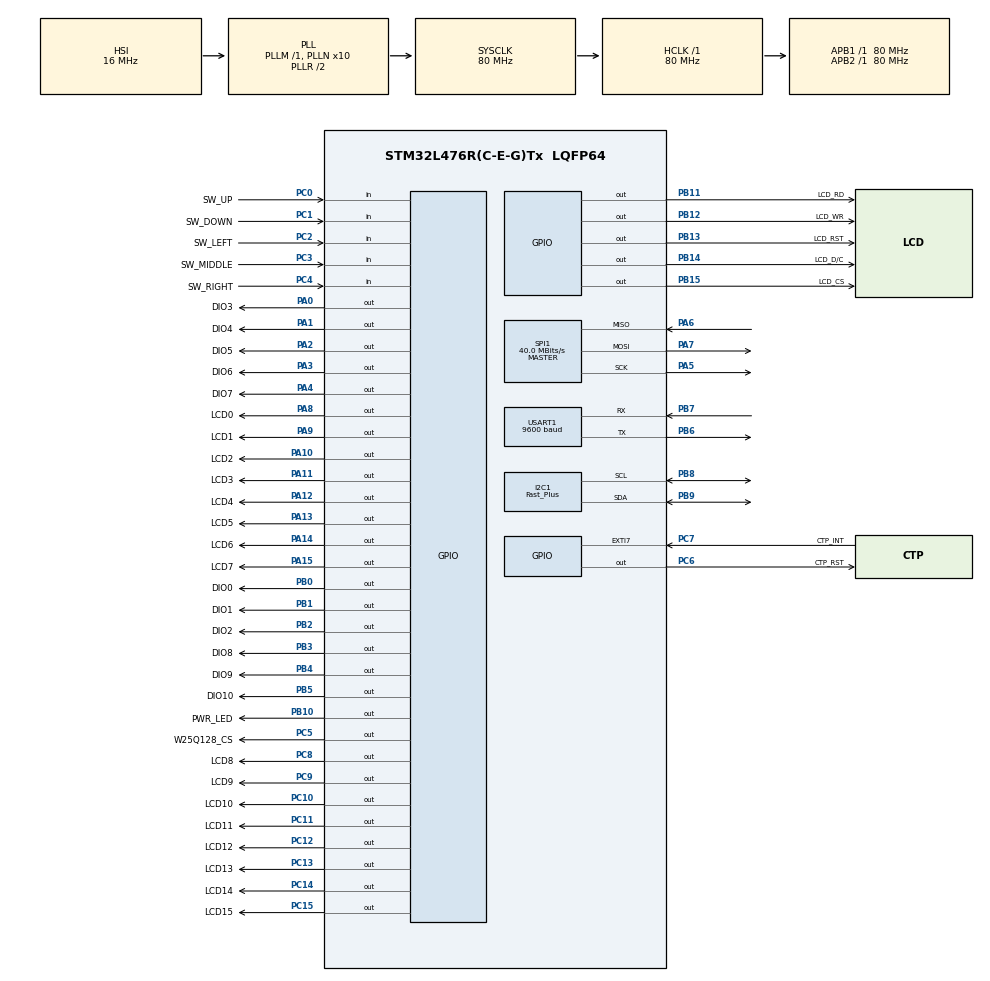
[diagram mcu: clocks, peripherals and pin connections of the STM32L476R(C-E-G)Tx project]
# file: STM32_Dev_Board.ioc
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FREERTOS.Tasks01=defaultTask,-3,128,StartDefaultTask,Default,NULL,Dynamic,NULL,NULL
FREERTOS.configTOTAL_HEAP_SIZE=20000
FREERTOS.configUSE_NEWLIB_REENTRANT=1
I2C1.I2C_Speed_Mode=I2C_Fast_Plus
I2C1.Timing=0x00300F33
Mcu.Family=STM32L4
Mcu.Name=STM32L476R(C-E-G)Tx
Mcu.Package=LQFP64
NVIC.EXTI9_5_IRQn=true\:5\:0\:true\:false\:true\:true\:true\:true\:true
NVIC.PriorityGroup=NVIC_PRIORITYGROUP_4
NVIC.TIM1_UP_TIM16_IRQn=true\:15\:0\:false\:false\:true\:false\:false\:true\:true
NVIC.TimeBase=TIM1_UP_TIM16_IRQn
NVIC.TimeBaseIP=TIM1
PA0.GPIO_Label=DIO3
PA0.Signal=GPIO_Output
PA1.GPIO_Label=DIO4
PA1.Signal=GPIO_Output
PA10.GPIO_Label=LCD2
PA10.Signal=GPIO_Output
PA11.GPIO_Label=LCD3
PA11.Signal=GPIO_Output
PA12.GPIO_Label=LCD4
PA12.Signal=GPIO_Output
PA13\ (JTMS-SWDIO).GPIO_Label=LCD5
PA13\ (JTMS-SWDIO).Signal=GPIO_Output
PA14\ (JTCK-SWCLK).GPIO_Label=LCD6
PA14\ (JTCK-SWCLK).Signal=GPIO_Output
PA15\ (JTDI).GPIO_Label=LCD7
PA15\ (JTDI).Signal=GPIO_Output
PA2.GPIO_Label=DIO5
PA2.Signal=GPIO_Output
PA3.GPIO_Label=DIO6
PA3.Signal=GPIO_Output
PA4.GPIO_Label=DIO7
PA4.Signal=GPIO_Output
PA5.Mode=Full_Duplex_Master
PA5.Signal=SPI1_SCK
PA6.Mode=Full_Duplex_Master
PA6.Signal=SPI1_MISO
PA7.Mode=Full_Duplex_Master
PA7.Signal=SPI1_MOSI
PA8.GPIO_Label=LCD0
PA8.Signal=GPIO_Output
PA9.GPIO_Label=LCD1
PA9.Signal=GPIO_Output
PB0.GPIO_Label=DIO0
PB0.Signal=GPIO_Output
PB1.GPIO_Label=DIO1
PB1.Signal=GPIO_Output
PB10.GPIO_Label=PWR_LED
PB10.Signal=GPIO_Output
PB11.GPIO_Label=LCD_RD
PB11.Signal=GPIO_Output
PB12.GPIO_Label=LCD_WR
PB12.Signal=GPIO_Output
PB13.GPIO_Label=LCD_RST
PB13.Signal=GPIO_Output
PB14.GPIO_Label=LCD_D/C
PB14.Signal=GPIO_Output
PB15.GPIO_Label=LCD_CS
PB15.Signal=GPIO_Output
PB2.GPIO_Label=DIO2
PB2.Signal=GPIO_Output
PB3\ (JTDO-TRACESWO).GPIO_Label=DIO8
PB3\ (JTDO-TRACESWO).Signal=GPIO_Output
PB4\ (NJTRST).GPIO_Label=DIO9
PB4\ (NJTRST).Signal=GPIO_Output
PB5.GPIO_Label=DIO10
PB5.Signal=GPIO_Output
PB6.Mode=Asynchronous
PB6.Signal=USART1_TX
PB7.Mode=Asynchronous
PB7.Signal=USART1_RX
PB8.Mode=I2C
PB8.Signal=I2C1_SCL
PB9.Mode=I2C
PB9.Signal=I2C1_SDA
PC0.GPIO_Label=SW_UP
PC0.Signal=GPIO_Input
PC1.GPIO_Label=SW_DOWN
PC1.Signal=GPIO_Input
PC10.GPIO_Label=LCD10
PC10.Signal=GPIO_Output
PC11.GPIO_Label=LCD11
PC11.Signal=GPIO_Output
PC12.GPIO_Label=LCD12
PC12.Signal=GPIO_Output
PC13.GPIO_Label=LCD13
PC13.Signal=GPIO_Output
PC14-OSC32_IN\ (PC14).GPIO_Label=LCD14
PC14-OSC32_IN\ (PC14).Signal=GPIO_Output
PC15-OSC32_OUT\ (PC15).GPIO_Label=LCD15
PC15-OSC32_OUT\ (PC15).Signal=GPIO_Output
PC2.GPIO_Label=SW_LEFT
PC2.Signal=GPIO_Input
PC3.GPIO_Label=SW_MIDDLE
PC3.Signal=GPIO_Input
PC4.GPIO_Label=SW_RIGHT
PC4.Signal=GPIO_Input
PC5.GPIO_Label=W25Q128_CS
PC5.Signal=GPIO_Output
PC6.GPIO_Label=CTP_RST
PC6.GPIO_PuPd=GPIO_NOPULL
PC6.PinState=GPIO_PIN_SET
PC6.Signal=GPIO_Output
PC7.GPIO_Label=CTP_INT
PC7.GPIO_ModeDefaultEXTI=GPIO_MODE_IT_RISING
PC7.GPIO_PuPd=GPIO_NOPULL
PC7.Signal=GPXTI7
PC8.GPIO_Label=LCD8
PC8.Signal=GPIO_Output
PC9.GPIO_Label=LCD9
PC9.Signal=GPIO_Output
ProjectManager.HeapSize=0x200
ProjectManager.StackSize=0x400
ProjectManager.TargetToolchain=STM32CubeIDE
RCC.ADCFreq_Value=64000000
RCC.AHBFreq_Value=80000000
RCC.APB1Freq_Value=80000000
RCC.APB1TimFreq_Value=80000000
RCC.APB2Freq_Value=80000000
RCC.APB2TimFreq_Value=80000000
RCC.CortexFreq_Value=80000000
RCC.HCLKFreq_Value=80000000
RCC.HSE_VALUE=8000000
RCC.HSI_VALUE=16000000
RCC.LSE_VALUE=32768
RCC.MSI_VALUE=4000000
RCC.PLLN=10
RCC.PLLSourceVirtual=RCC_PLLSOURCE_HSI
RCC.SYSCLKFreq_VALUE=80000000
RCC.SYSCLKSource=RCC_SYSCLKSOURCE_PLLCLK
RCC.USBFreq_Value=64000000
RCC.VCOOutputFreq_Value=160000000
SPI1.BaudRatePrescaler=SPI_BAUDRATEPRESCALER_2
SPI1.CalculateBaudRate=40.0 MBits/s
SPI1.Direction=SPI_DIRECTION_2LINES
SPI1.Mode=SPI_MODE_MASTER
SPI1.VirtualType=VM_MASTER
STMicroelectronics.X-CUBE-TOUCHGFX.4.20.0.tgfx_custom_height=320
STMicroelectronics.X-CUBE-TOUCHGFX.4.20.0.tgfx_custom_width=480
STMicroelectronics.X-CUBE-TOUCHGFX.4.20.0.tgfx_oswrapper=CMSIS V2
STMicroelectronics.X-CUBE-TOUCHGFX.4.20.0_IsPackSelfContextualization=true
USART1.BaudRate=9600
USART1.MSBFirstParam=ADVFEATURE_MSBFIRST_DISABLE
USART1.VirtualMode-Asynchronous=VM_ASYNC
USART1.WordLength=WORDLENGTH_8B
VP_CRC_VS_CRC.Mode=CRC_Activate
VP_FREERTOS_VS_CMSIS_V1.Mode=CMSIS_V1
VP_SYS_VS_tim1.Mode=TIM1
board=custom

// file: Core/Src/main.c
/* USER CODE BEGIN Header */
/**
  ******************************************************************************
  * @file           : main.c
  * @brief          : Main program body
  ******************************************************************************
  * @attention
  *
  * Copyright (c) 2022 STMicroelectronics.
  * All rights reserved.
  *
  * This software is licensed under terms that can be found in the LICENSE file
  * in the root directory of this software component.
  * If no LICENSE file comes with this software, it is provided AS-IS.
  *
  ******************************************************************************
  */
/* USER CODE END Header */
#include "main.h"
#include "cmsis_os.h"
#include "drivers/FT5446.h"

/* USER CODE BEGIN Includes */
#include "DevBoard.h"

/* USER CODE END Includes */

CRC_HandleTypeDef hcrc;

I2C_HandleTypeDef hi2c1;

SPI_HandleTypeDef hspi1;

UART_HandleTypeDef huart1;

osThreadId defaultTaskHandle;

void SystemClock_Config(void);
static void MX_GPIO_Init(void);
static void MX_I2C1_Init(void);
static void MX_SPI1_Init(void);
static void MX_USART1_UART_Init(void);
static void MX_CRC_Init(void);
void StartDefaultTask(void const * argument);

/* USER CODE BEGIN 0 */

//CTP Interrupt Callback function
void HAL_GPIO_EXTI_Callback(uint16_t GPIO_Pin)
{
	//Touch screen interrupt has occured. Notify the touch screen thread.
	xTaskNotifyFromISR( touchTaskHandle, 0, eSetValueWithOverwrite, pdFALSE);
}

/* USER CODE END 0 */

int main(void)
{

  /* MCU Configuration--------------------------------------------------------*/

  /* Reset of all peripherals, Initializes the Flash interface and the Systick. */
  HAL_Init();

  /* Configure the system clock */
  SystemClock_Config();

  /* Initialize all configured peripherals */
  MX_GPIO_Init();
  MX_I2C1_Init();
  MX_SPI1_Init();
  MX_USART1_UART_Init();
  MX_CRC_Init();
  /* USER CODE BEGIN 2 */

  /*
   * Low level initialisations
   */
  //Turn the Power LED on
  HAL_GPIO_WritePin(PWR_LED_GPIO_Port, PWR_LED_Pin, GPIO_PIN_SET);

  //Initialise the display using the display manager
  DM_Init();

  //Bring the CTP out of reset
  //Dont' forget that the top half of PORTC is used by the LCD Data
  HAL_GPIO_WritePin(CTP_RST_GPIO_Port, CTP_RST_Pin, GPIO_PIN_SET);
  HAL_Delay(10);

  FT5446_init();

  /* USER CODE END 2 */

  /* Create the thread(s) */
  /* definition and creation of defaultTask */
  osThreadDef(defaultTask, StartDefaultTask, osPriorityIdle, 0, 128);
  defaultTaskHandle = osThreadCreate(osThread(defaultTask), NULL);

  /* USER CODE BEGIN RTOS_THREADS */

  //Initialise the threads which run the peripherals on this board
  DevBoardBegin();

  /* USER CODE END RTOS_THREADS */

  /* Start scheduler */
  osKernelStart();

  /* We should never get here as control is now taken by the scheduler */
  /* Infinite loop */
  while (1)
  {

  }
}

void SystemClock_Config(void)
{
  RCC_OscInitTypeDef RCC_OscInitStruct = {0};
  RCC_ClkInitTypeDef RCC_ClkInitStruct = {0};

  /** Configure the main internal regulator output voltage
  */
  if (HAL_PWREx_ControlVoltageScaling(PWR_REGULATOR_VOLTAGE_SCALE1) != HAL_OK)
  {
    Error_Handler();
  }

  /** Initializes the RCC Oscillators according to the specified parameters
  * in the RCC_OscInitTypeDef structure.
  */
  RCC_OscInitStruct.OscillatorType = RCC_OSCILLATORTYPE_HSI;
  RCC_OscInitStruct.HSIState = RCC_HSI_ON;
  RCC_OscInitStruct.HSICalibrationValue = RCC_HSICALIBRATION_DEFAULT;
  RCC_OscInitStruct.PLL.PLLState = RCC_PLL_ON;
  RCC_OscInitStruct.PLL.PLLSource = RCC_PLLSOURCE_HSI;
  RCC_OscInitStruct.PLL.PLLM = 1;
  RCC_OscInitStruct.PLL.PLLN = 10;
  RCC_OscInitStruct.PLL.PLLP = RCC_PLLP_DIV7;
  RCC_OscInitStruct.PLL.PLLQ = RCC_PLLQ_DIV2;
  RCC_OscInitStruct.PLL.PLLR = RCC_PLLR_DIV2;
  if (HAL_RCC_OscConfig(&RCC_OscInitStruct) != HAL_OK)
  {
    Error_Handler();
  }

  /** Initializes the CPU, AHB and APB buses clocks
  */
  RCC_ClkInitStruct.ClockType = RCC_CLOCKTYPE_HCLK|RCC_CLOCKTYPE_SYSCLK
                              |RCC_CLOCKTYPE_PCLK1|RCC_CLOCKTYPE_PCLK2;
  RCC_ClkInitStruct.SYSCLKSource = RCC_SYSCLKSOURCE_PLLCLK;
  RCC_ClkInitStruct.AHBCLKDivider = RCC_SYSCLK_DIV1;
  RCC_ClkInitStruct.APB1CLKDivider = RCC_HCLK_DIV1;
  RCC_ClkInitStruct.APB2CLKDivider = RCC_HCLK_DIV1;

  if (HAL_RCC_ClockConfig(&RCC_ClkInitStruct, FLASH_LATENCY_4) != HAL_OK)
  {
    Error_Handler();
  }
}

static void MX_CRC_Init(void)
{

  hcrc.Instance = CRC;
  hcrc.Init.DefaultPolynomialUse = DEFAULT_POLYNOMIAL_ENABLE;
  hcrc.Init.DefaultInitValueUse = DEFAULT_INIT_VALUE_ENABLE;
  hcrc.Init.InputDataInversionMode = CRC_INPUTDATA_INVERSION_NONE;
  hcrc.Init.OutputDataInversionMode = CRC_OUTPUTDATA_INVERSION_DISABLE;
  hcrc.InputDataFormat = CRC_INPUTDATA_FORMAT_BYTES;
  if (HAL_CRC_Init(&hcrc) != HAL_OK)
  {
    Error_Handler();
  }

}

static void MX_I2C1_Init(void)
{

  hi2c1.Instance = I2C1;
  hi2c1.Init.Timing = 0x10909CEC;
  hi2c1.Init.OwnAddress1 = 0;
  hi2c1.Init.AddressingMode = I2C_ADDRESSINGMODE_7BIT;
  hi2c1.Init.DualAddressMode = I2C_DUALADDRESS_DISABLE;
  hi2c1.Init.OwnAddress2 = 0;
  hi2c1.Init.OwnAddress2Masks = I2C_OA2_NOMASK;
  hi2c1.Init.GeneralCallMode = I2C_GENERALCALL_DISABLE;
  hi2c1.Init.NoStretchMode = I2C_NOSTRETCH_DISABLE;
  if (HAL_I2C_Init(&hi2c1) != HAL_OK)
  {
    Error_Handler();
  }

  /** Configure Analogue filter
  */
  if (HAL_I2CEx_ConfigAnalogFilter(&hi2c1, I2C_ANALOGFILTER_ENABLE) != HAL_OK)
  {
    Error_Handler();
  }

  /** Configure Digital filter
  */
  if (HAL_I2CEx_ConfigDigitalFilter(&hi2c1, 0) != HAL_OK)
  {
    Error_Handler();
  }

}

static void MX_SPI1_Init(void)
{

  /* SPI1 parameter configuration*/
  hspi1.Instance = SPI1;
  hspi1.Init.Mode = SPI_MODE_MASTER;
  hspi1.Init.Direction = SPI_DIRECTION_2LINES;
  hspi1.Init.DataSize = SPI_DATASIZE_4BIT;
  hspi1.Init.CLKPolarity = SPI_POLARITY_LOW;
  hspi1.Init.CLKPhase = SPI_PHASE_1EDGE;
  hspi1.Init.NSS = SPI_NSS_SOFT;
  hspi1.Init.BaudRatePrescaler = SPI_BAUDRATEPRESCALER_2;
  hspi1.Init.FirstBit = SPI_FIRSTBIT_MSB;
  hspi1.Init.TIMode = SPI_TIMODE_DISABLE;
  hspi1.Init.CRCCalculation = SPI_CRCCALCULATION_DISABLE;
  hspi1.Init.CRCPolynomial = 7;
  hspi1.Init.CRCLength = SPI_CRC_LENGTH_DATASIZE;
  hspi1.Init.NSSPMode = SPI_NSS_PULSE_ENABLE;
  if (HAL_SPI_Init(&hspi1) != HAL_OK)
  {
    Error_Handler();
  }

}

static void MX_USART1_UART_Init(void)
{

  huart1.Instance = USART1;
  huart1.Init.BaudRate = 9600;
  huart1.Init.WordLength = UART_WORDLENGTH_8B;
  huart1.Init.StopBits = UART_STOPBITS_1;
  huart1.Init.Parity = UART_PARITY_NONE;
  huart1.Init.Mode = UART_MODE_TX_RX;
  huart1.Init.HwFlowCtl = UART_HWCONTROL_NONE;
  huart1.Init.OverSampling = UART_OVERSAMPLING_16;
  huart1.Init.OneBitSampling = UART_ONE_BIT_SAMPLE_DISABLE;
  huart1.AdvancedInit.AdvFeatureInit = UART_ADVFEATURE_NO_INIT;
  if (HAL_UART_Init(&huart1) != HAL_OK)
  {
    Error_Handler();
  }

}

static void MX_GPIO_Init(void)
{
  GPIO_InitTypeDef GPIO_InitStruct = {0};

  /* GPIO Ports Clock Enable */
  __HAL_RCC_GPIOC_CLK_ENABLE();
  __HAL_RCC_GPIOA_CLK_ENABLE();
  __HAL_RCC_GPIOB_CLK_ENABLE();

  /*Configure GPIO pin Output Level */
  HAL_GPIO_WritePin(GPIOC, LCD13_Pin|LCD14_Pin|LCD15_Pin|W25Q128_CS_Pin
                          |LCD8_Pin|LCD9_Pin|LCD10_Pin|LCD11_Pin
                          |LCD12_Pin, GPIO_PIN_RESET);

  /*Configure GPIO pin Output Level */
  HAL_GPIO_WritePin(GPIOA, DIO3_Pin|DIO4_Pin|DIO5_Pin|DIO6_Pin
                          |DIO7_Pin|LCD0_Pin|LCD1_Pin|LCD2_Pin
                          |LCD3_Pin|LCD4_Pin|LCD5_Pin|LCD6_Pin
                          |LCD7_Pin, GPIO_PIN_RESET);

  /*Configure GPIO pin Output Level */
  HAL_GPIO_WritePin(GPIOB, DIO0_Pin|DIO1_Pin|DIO2_Pin|PWR_LED_Pin
                          |LCD_RD_Pin|LCD_WR_Pin|LCD_RST_Pin|LCD_D_C_Pin
                          |LCD_CS_Pin|DIO8_Pin|DIO9_Pin|DIO10_Pin, GPIO_PIN_RESET);

  /*Configure GPIO pin Output Level */
  HAL_GPIO_WritePin(CTP_RST_GPIO_Port, CTP_RST_Pin, GPIO_PIN_SET);

  /*Configure GPIO pins : LCD13_Pin LCD14_Pin LCD15_Pin W25Q128_CS_Pin
                           CTP_RST_Pin LCD8_Pin LCD9_Pin LCD10_Pin
                           LCD11_Pin LCD12_Pin */
  GPIO_InitStruct.Pin = LCD13_Pin|LCD14_Pin|LCD15_Pin|W25Q128_CS_Pin
                          |CTP_RST_Pin|LCD8_Pin|LCD9_Pin|LCD10_Pin
                          |LCD11_Pin|LCD12_Pin;
  GPIO_InitStruct.Mode = GPIO_MODE_OUTPUT_PP;
  GPIO_InitStruct.Pull = GPIO_NOPULL;
  GPIO_InitStruct.Speed = GPIO_SPEED_FREQ_LOW;
  HAL_GPIO_Init(GPIOC, &GPIO_InitStruct);

  /*Configure GPIO pins : SW_UP_Pin SW_DOWN_Pin SW_LEFT_Pin SW_MIDDLE_Pin
                           SW_RIGHT_Pin */
  GPIO_InitStruct.Pin = SW_UP_Pin|SW_DOWN_Pin|SW_LEFT_Pin|SW_MIDDLE_Pin
                          |SW_RIGHT_Pin;
  GPIO_InitStruct.Mode = GPIO_MODE_INPUT;
  GPIO_InitStruct.Pull = GPIO_NOPULL;
  HAL_GPIO_Init(GPIOC, &GPIO_InitStruct);

  /*Configure GPIO pins : DIO3_Pin DIO4_Pin DIO5_Pin DIO6_Pin
                           DIO7_Pin LCD0_Pin LCD1_Pin LCD2_Pin
                           LCD3_Pin LCD4_Pin LCD5_Pin LCD6_Pin
                           LCD7_Pin */
  GPIO_InitStruct.Pin = DIO3_Pin|DIO4_Pin|DIO5_Pin|DIO6_Pin
                          |DIO7_Pin|LCD0_Pin|LCD1_Pin|LCD2_Pin
                          |LCD3_Pin|LCD4_Pin|LCD5_Pin|LCD6_Pin
                          |LCD7_Pin;
  GPIO_InitStruct.Mode = GPIO_MODE_OUTPUT_PP;
  GPIO_InitStruct.Pull = GPIO_NOPULL;
  GPIO_InitStruct.Speed = GPIO_SPEED_FREQ_LOW;
  HAL_GPIO_Init(GPIOA, &GPIO_InitStruct);

  /*Configure GPIO pins : DIO0_Pin DIO1_Pin DIO2_Pin PWR_LED_Pin
                           LCD_RD_Pin LCD_WR_Pin LCD_RST_Pin LCD_D_C_Pin
                           LCD_CS_Pin DIO8_Pin DIO9_Pin DIO10_Pin */
  GPIO_InitStruct.Pin = DIO0_Pin|DIO1_Pin|DIO2_Pin|PWR_LED_Pin
                          |LCD_RD_Pin|LCD_WR_Pin|LCD_RST_Pin|LCD_D_C_Pin
                          |LCD_CS_Pin|DIO8_Pin|DIO9_Pin|DIO10_Pin;
  GPIO_InitStruct.Mode = GPIO_MODE_OUTPUT_PP;
  GPIO_InitStruct.Pull = GPIO_NOPULL;
  GPIO_InitStruct.Speed = GPIO_SPEED_FREQ_LOW;
  HAL_GPIO_Init(GPIOB, &GPIO_InitStruct);

  /*Configure GPIO pin : CTP_INT_Pin */
  GPIO_InitStruct.Pin = CTP_INT_Pin;
  GPIO_InitStruct.Mode = GPIO_MODE_IT_RISING;
  GPIO_InitStruct.Pull = GPIO_NOPULL;
  HAL_GPIO_Init(CTP_INT_GPIO_Port, &GPIO_InitStruct);

  /* EXTI interrupt init*/
  HAL_NVIC_SetPriority(EXTI9_5_IRQn, 5, 0);
  HAL_NVIC_EnableIRQ(EXTI9_5_IRQn);

}

void StartDefaultTask(void const * argument)
{
  for(;;)
  {
  }
}

void HAL_TIM_PeriodElapsedCallback(TIM_HandleTypeDef *htim)
{
  if (htim->Instance == TIM1) {
    HAL_IncTick();
  }
}

void Error_Handler(void)
{
  __disable_irq();
  while (1)
  {
  }
}
